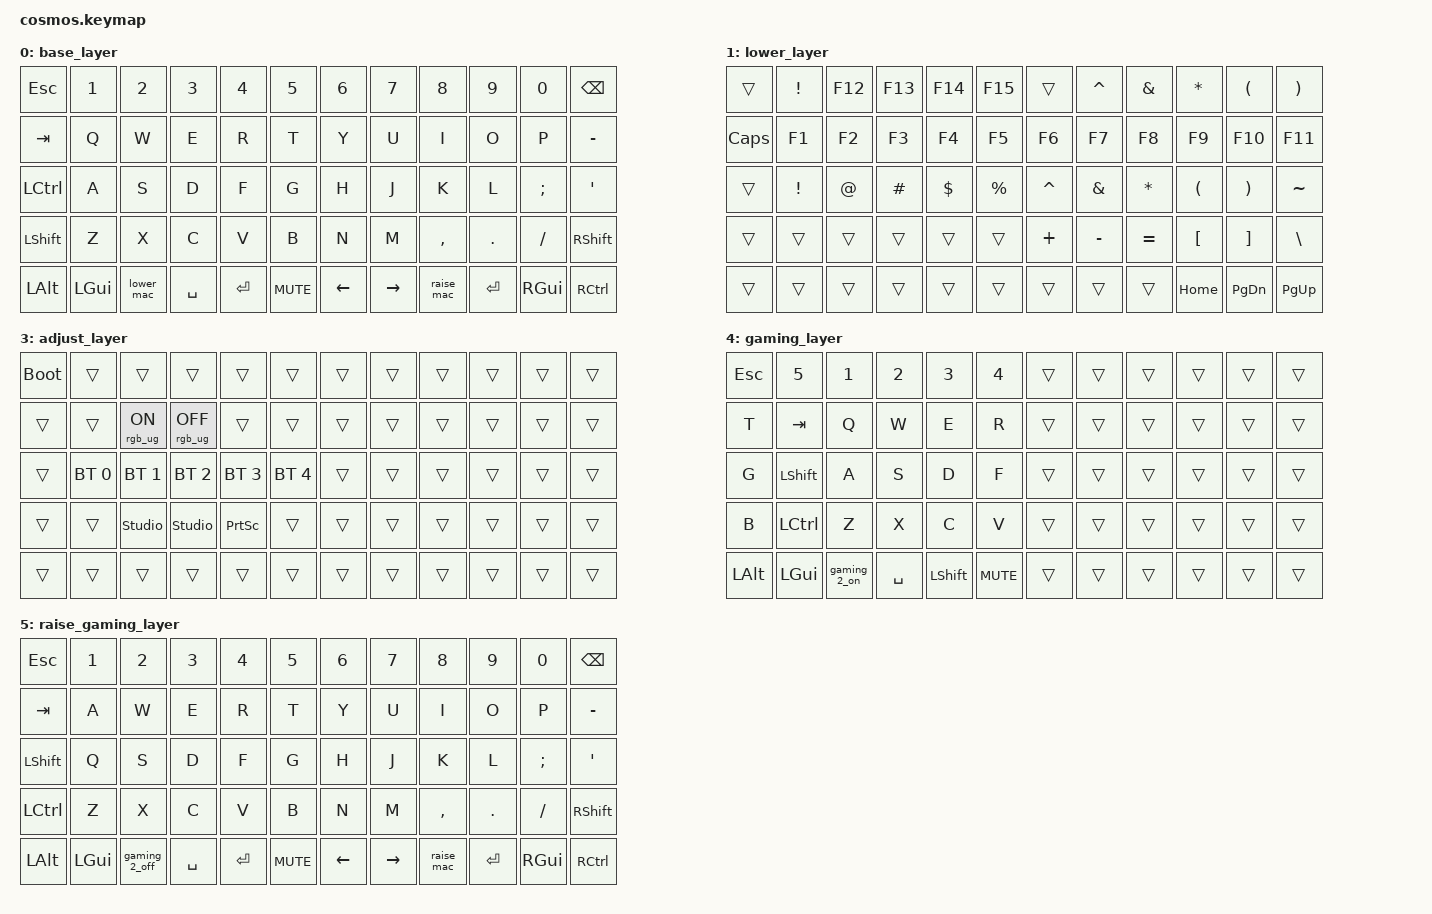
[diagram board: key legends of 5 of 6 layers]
/*
 * Cosmos Keyboard — Keymap
 * 5 rows x 14 cols (7 per half)
 * Layers: Base (QWERTY), Lower, Raise, Adjust
 */

#include <behaviors.dtsi>
#include <dt-bindings/zmk/keys.h>
#include <dt-bindings/zmk/bt.h>
#include <dt-bindings/zmk/rgb.h>
#include <dt-bindings/led/led.h>

#define BASE  0
#define LOWER 1
#define RAISE 2
#define ADJUST  3   // BT/system — used by conditional_layers
#define GAMING  4   // actual gaming layer
#define GAMING_2 5    // to access other keys while gaming

/* Include the combined behaviors file */
#include "cosmos_behaviors.dtsi"

/ {


    conditional_layers {
        compatible = "zmk,conditional-layers";
        adjust_layer {
            if-layers = <LOWER RAISE>;
            then-layer = <ADJUST>;    // now correctly separate
        };
    };

    keymap {
        compatible = "zmk,keymap";

        /* ─── Layer 0: Base (QWERTY) ─────────────────────────────────────
         * ┌──────┬──────┬──────┬──────┬──────┬──────┬──────┐  ┌──────┬──────┬──────┬──────┬──────┬──────┬──────┐
         * │ ESC  │  1   │  2   │  3   │  4   │  5   │  6   │  │  7   │  8   │  9   │  0   │  -   │  =   │ BSPC │
         * ├──────┼──────┼──────┼──────┼──────┼──────┼──────┤  ├──────┼──────┼──────┼──────┼──────┼──────┼──────┤
         * │ TAB  │  Q   │  W   │  E   │  R   │  T   │  [   │  │  ]   │  Y   │  U   │  I   │  O   │  P   │  \   │
         * ├──────┼──────┼──────┼──────┼──────┼──────┼──────┤  ├──────┼──────┼──────┼──────┼──────┼──────┼──────┤
         * │ CAPS │  A   │  S   │  D   │  F   │  G   │  (   │  │  )   │  H   │  J   │  K   │  L   │  ;   │  '   │
         * ├──────┼──────┼──────┼──────┼──────┼──────┼──────┤  ├──────┼──────┼──────┼──────┼──────┼──────┼──────┤
         * │LSHFT │  Z   │  X   │  C   │  V   │  B   │  {   │  │  }   │  N   │  M   │  ,   │  .   │  /   │RSHFT │
         * ├──────┼──────┼──────┼──────┼──────┼──────┼──────┤  ├──────┼──────┼──────┼──────┼──────┼──────┼──────┤
         * │ LCTL │ LGUI │ LALT │  `   │LOWER │ SPC  │ DEL  │  │ ENT  │ SPC  │RAISE │ LEFT │ DOWN │  UP  │RIGHT │
         * └──────┴──────┴──────┴──────┴──────┴──────┴──────┘  └──────┴──────┴──────┴──────┴──────┴──────┴──────┘
         */
        base_layer {
            bindings = <
                &kp ESC   &kp N1    &kp N2      &kp N3    &kp N4    &kp N5             &kp N6     &kp N7   &kp N8     &kp N9    &kp N0    &kp BSPC     
                &kp TAB   &kp Q     &kp W       &kp E     &kp R     &kp T              &kp Y     &kp U     &kp I      &kp O     &kp P     &kp MINUS     
                &kp LCTRL &kp A     &kp S       &kp D     &kp F     &kp G              &kp H     &kp J     &kp K      &kp L     &kp SEMI  &kp SQT    
                &kp LSHFT &kp Z     &kp X       &kp C     &kp V     &kp B              &kp N     &kp M     &kp COMMA  &kp DOT   &kp FSLH  &kp RSHFT    
                &kp LALT  &kp LGUI  &lower_mac  &kp SPACE &kp RET   &kp C_MUTE         &kp LEFT  &kp RIGHT &raise_mac &kp RET   &kp RGUI  &kp RCTRL
            >;
            sensor-bindings = <&inc_dec_kp C_VOL_DN C_VOL_UP>;
        };

        /* ─── Layer 1: Lower — Symbols & F-Keys ─────────────────────────*/
        lower_layer {
            bindings = <
                &trans    &kp EXCL &kp F12  &kp F13  &kp F14 &kp F15                &trans     &kp CARET &kp AMPS  &kp STAR  &kp LPAR  &kp RPAR 
                &kp CAPS &kp F1   &kp F2   &kp F3   &kp F4   &kp F5                &kp F6     &kp F7     &kp F8    &kp F9    &kp F10   &kp F11     
                &trans   &kp EXCL &kp AT  &kp HASH &kp DOLLAR &kp PRCNT             &kp CARET  &kp AMPS  &kp ASTRK &kp LPAR  &kp RPAR  &kp TILDE
                &trans    &trans   &trans   &trans   &trans   &trans                &kp PLUS   &kp MINUS  &kp EQUAL &kp LBKT  &kp RBKT  &kp BSLH 
                &trans    &trans   &trans   &trans   &trans   &trans                &trans     &trans    &trans    &kp HOME  &kp PG_DN &kp PG_UP
            >;
            sensor-bindings = <&inc_dec_kp C_PREV C_NEXT>;
        };

        /* ─── Layer 2: Raise — Navigation & Numpad ───────────────────────*/
        raise_layer {
            bindings = <
                &trans    &trans   &trans   &trans   &trans   &trans                &trans   &trans   &kp KP_N7 &kp KP_N8   &kp KP_N9     &kp KP_MINUS
                &kp GRAVE &kp N1    &kp N2   &kp N3   &kp N4   &kp N5               &kp N6     &kp N7   &kp N8    &kp N9    &kp N0     &trans
                &trans    &trans   &trans   &trans   &trans   &trans                &trans   &kp LEFT &kp DOWN  &kp UP   &kp RIGHT     &kp KP_ENTER
                &trans    &trans   &trans   &trans   &trans   &trans                &trans   &trans   &kp KP_N0 &trans      &kp KP_DOT    &trans     
                &trans    &trans   &trans   &trans   &trans   &kp C_PLAY_PAUSE      &trans   &trans   &trans   &kp HOME &kp PG_DN &kp PG_UP &kp END
            >;
            sensor-bindings = <&inc_dec_kp C_PREV C_NEXT>;
        };
        

        /* ─── Layer 3: Adjust — BT & System (LOWER + RAISE) ─────────────*/
        adjust_layer {
            bindings = <
                &bootloader &trans       &trans           &trans         &trans           &trans                          &trans    &trans    &trans    &trans    &trans    &trans
                &trans      &trans       &rgb_ug RGB_ON   &rgb_ug RGB_OFF &trans           &trans                          &trans    &trans    &trans    &trans    &trans    &trans
                &trans      &bt BT_SEL 0 &bt BT_SEL 1     &bt BT_SEL 2   &bt BT_SEL 3     &bt BT_SEL 4                    &trans    &trans    &trans    &trans    &trans    &trans
                &trans      &trans       &studio_unlock   &studio_unlock &kp PRINTSCREEN  &trans                          &trans    &trans    &trans    &trans    &trans    &trans
                &trans      &trans       &trans           &trans         &trans           &trans                          &trans    &trans    &trans    &trans    &trans    &trans
            >;
            sensor-bindings = <&inc_dec_kp C_VOL_DN C_VOL_UP>;
        };

        /* ─── Layer 4: Gaming - Shifted over one for comfort ────────────────────────────────────────────────
        * ┌──────┬──────┬──────┬──────┬──────┬──────┐  ┌──────┬──────┬──────┬──────┬──────┬──────┐
        * │ ESC  │  1   │  2   │  3   │  4   │  5   │  │      │      │      │      │      │      │
        * ├──────┼──────┼──────┼──────┼──────┼──────┤  ├──────┼──────┼──────┼──────┼──────┼──────┤
        * │  T   │ TAB  │  Q   │  W   │  E   │  R   │  │      │      │      │      │      │      │
        * ├──────┼──────┼──────┼──────┼──────┼──────┤  ├──────┼──────┼──────┼──────┼──────┼──────┤
        * │  G   │LSHFT │  A   │  S   │  D   │  F   │  │      │      │      │      │      │      │
        * ├──────┼──────┼──────┼──────┼──────┼──────┤  ├──────┼──────┼──────┼──────┼──────┼──────┤
        * │  B   │LCTRL │  Z   │  X   │  C   │  V   │  │      │      │      │      │      │      │
        * ├──────┼──────┼──────┼──────┼──────┼──────┤  ├──────┼──────┼──────┼──────┼──────┼──────┤
        * │ LALT │ LGUI │LCTRL │ SPC  │LSHFT │ MUTE │  │      │      │      │      │      │      │
        * └──────┴──────┴──────┴──────┴──────┴──────┘  └──────┴──────┴──────┴──────┴──────┴──────┘
        */
        gaming_layer {
            bindings = <
                &kp ESC   &kp N5    &kp N1    &kp N2    &kp N3    &kp N4             &trans    &trans    &trans    &trans    &trans    &trans
                &kp T     &kp TAB   &kp Q     &kp W     &kp E     &kp R              &trans    &trans    &trans    &trans    &trans    &trans
                &kp G     &kp LSHFT &kp A     &kp S     &kp D     &kp F              &trans    &trans    &trans    &trans    &trans    &trans
                &kp B     &kp LCTRL &kp Z     &kp X     &kp C     &kp V              &trans    &trans    &trans    &trans    &trans    &trans
                &kp LALT  &kp LGUI  &gaming_2_on &kp SPACE &kp LSHFT &kp C_MUTE        &trans    &trans    &trans    &trans    &trans    &trans
            >;
            sensor-bindings = <&inc_dec_kp C_VOL_DN C_VOL_UP>;
        };
        raise_gaming_layer {
            bindings = <
                &kp ESC   &kp N1    &kp N2      &kp N3    &kp N4    &kp N5             &kp N6     &kp N7   &kp N8     &kp N9    &kp N0    &kp BSPC     
                &kp TAB   &kp A     &kp W       &kp E     &kp R     &kp T              &kp Y     &kp U     &kp I      &kp O     &kp P     &kp MINUS     
                &kp LSHFT &kp Q     &kp S       &kp D     &kp F     &kp G              &kp H     &kp J     &kp K      &kp L     &kp SEMI  &kp SQT    
                &kp LCTRL &kp Z     &kp X       &kp C     &kp V     &kp B              &kp N     &kp M     &kp COMMA  &kp DOT   &kp FSLH  &kp RSHFT    
                &kp LALT  &kp LGUI  &gaming_2_off  &kp SPACE &kp RET   &kp C_MUTE         &kp LEFT  &kp RIGHT &raise_mac &kp RET   &kp RGUI  &kp RCTRL
            >;
            sensor-bindings = <&inc_dec_kp C_VOL_DN C_VOL_UP>;
        };
    };
};
